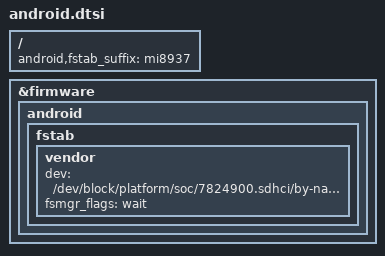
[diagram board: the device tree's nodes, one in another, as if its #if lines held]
/ {
	android,fstab_suffix = "mi8937";
};

&firmware {
	android {
#ifdef MI8937_V2
		/delete-node/ fstab;
#endif
		/delete-node/ vbmeta;
#ifndef MI8937_V2
		fstab {
			vendor {
				dev = "/dev/block/platform/soc/7824900.sdhci/by-name/cust";
				fsmgr_flags = "wait";
			};
		};
#endif
	};
};
